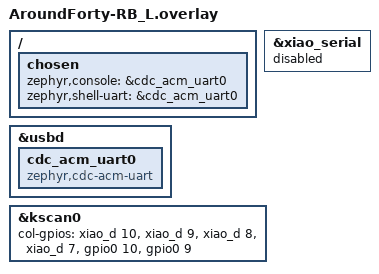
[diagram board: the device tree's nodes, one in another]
#include "AroundForty-RB.dtsi"

&xiao_serial { status = "disabled"; };

&usbd {
    cdc_acm_uart0: cdc_acm_uart0 {
        compatible = "zephyr,cdc-acm-uart";
    };
};

/ {
    chosen {
        zephyr,console = &cdc_acm_uart0;
        zephyr,shell-uart = &cdc_acm_uart0;
    };
};

&kscan0 {
        col-gpios
            = <&xiao_d 10 GPIO_ACTIVE_HIGH>
            , <&xiao_d 9 GPIO_ACTIVE_HIGH> 
            , <&xiao_d 8 GPIO_ACTIVE_HIGH> 
            , <&xiao_d 7 GPIO_ACTIVE_HIGH> 
            , <&gpio0 10 GPIO_ACTIVE_HIGH>
            , <&gpio0 9 GPIO_ACTIVE_HIGH>
            ;
};
